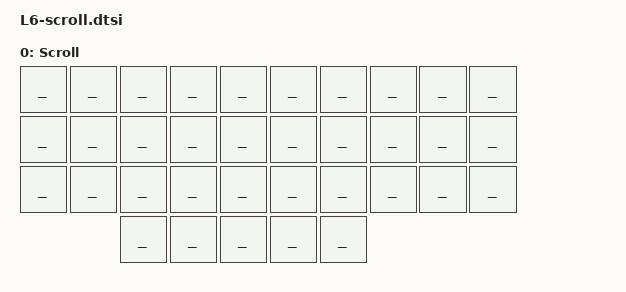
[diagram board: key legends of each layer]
/**
 *
 */

/ {
  keymap {
    compatible = "zmk,keymap";

	scroll_layer {
		label = "Scroll";
		bindings = <
//	╭───────────────┬───────────────┬───────────────┬───────────────┬───────────────╮   ╭───────────────┬───────────────┬───────────────┬───────────────┬───────────────╮
	________		________    	________		________		________			________        ________     	________        ________        ________
//	├───────────────┼───────────────┼───────────────┼───────────────┼───────────────┤   ├───────────────├───────────────┼───────────────┼───────────────┼───────────────┤
	________		________    	________		________		________			________        ________     	________        ________        ________
//	├───────────────┼───────────────┼───────────────┼───────────────┼───────────────┤   ├───────────────├───────────────┼───────────────┼───────────────┼───────────────┤
	________		________    	________		________		________			________        ________     	________        ________        ________
//	╰───────────────┴───────────────┼───────────────┼───────────────┼───────────────┤   ├───────────────├───────────────┼───────────────┼───────────────┴───────────────╯
	       							________		________        ________           	________		________
//                                                  ╰───────────────┴───────────────╯   ╰───────────────┴───────────────╯
			>;
		};
	};
};
